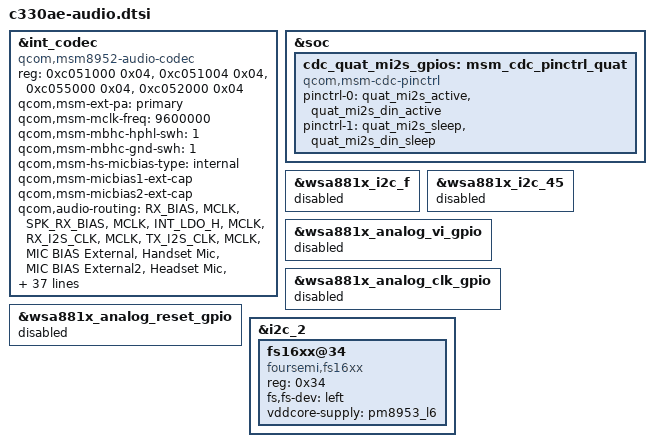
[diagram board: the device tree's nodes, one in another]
&int_codec {
	compatible = "qcom,msm8952-audio-codec";
	status = "okay";

	reg = <0xc051000 0x04>,
		  <0xc051004 0x04>,
		  <0xc055000 0x04>,
		  <0xc052000 0x04>;
	reg-names = "csr_gp_io_mux_mic_ctl",
		  "csr_gp_io_mux_spkr_ctl",
		  "csr_gp_io_lpaif_pri_pcm_pri_mode_muxsel",
		  "csr_gp_io_mux_quin_ctl";

	qcom,msm-ext-pa = "primary";
	qcom,msm-mclk-freq = <9600000>;

	qcom,msm-mbhc-hphl-swh = <1>;
	qcom,msm-mbhc-gnd-swh = <1>;
	qcom,msm-hs-micbias-type = "internal";
	qcom,msm-micbias1-ext-cap;
	qcom,msm-micbias2-ext-cap;

	qcom,audio-routing =
		"RX_BIAS", "MCLK",
		"SPK_RX_BIAS", "MCLK",
		"INT_LDO_H", "MCLK",
		"RX_I2S_CLK", "MCLK",
		"TX_I2S_CLK", "MCLK",
		"MIC BIAS External", "Handset Mic",
		"MIC BIAS External2", "Headset Mic",
		"MIC BIAS External", "Secondary Mic",
		"AMIC1", "MIC BIAS External",
		"AMIC2", "MIC BIAS External2",
		"AMIC3", "MIC BIAS External",
		"ADC1_IN", "ADC1_OUT",
		"ADC2_IN", "ADC2_OUT",
		"ADC3_IN", "ADC3_OUT",
		"PDM_IN_RX1", "PDM_OUT_RX1",
		"PDM_IN_RX2", "PDM_OUT_RX2",
		"PDM_IN_RX3", "PDM_OUT_RX3";

	/delete-property/ qcom,cdc-us-euro-gpios;
	/delete-property/ qcom,cdc-us-eu-gpios;
	/delete-property/ qcom,quin-mi2s-gpios;
	/delete-property/ asoc-wsa-codec-names;
	/delete-property/ asoc-wsa-codec-prefixes;
	/delete-property/ msm-vdd-wsa-switch-supply;
	/delete-property/ qcom,msm-vdd-wsa-switch-voltage;
	/delete-property/ qcom,msm-vdd-wsa-switch-current;

	qcom,msm-ext-I2S = "Quaternary";
	qcom,msm-ext-i2s-codec-num = <1>;
	qcom,codec-dai-left-name = "fs16xx_codec_left";
	qcom,codec-left-name = "fs16xx.2-0034";
	asoc-cpu = <&dai_pri_auxpcm>,
		<&dai_mi2s0>, <&dai_mi2s1>,
		<&dai_mi2s2>, <&dai_mi2s3>,
		<&dai_mi2s4>, <&dai_mi2s5>,
		<&sb_0_rx>, <&sb_0_tx>, <&sb_1_rx>, <&sb_1_tx>,
		<&sb_3_rx>, <&sb_3_tx>, <&sb_4_rx>, <&sb_4_tx>,
		<&bt_sco_rx>, <&bt_sco_tx>,
		<&int_fm_rx>, <&int_fm_tx>,
		<&afe_pcm_rx>, <&afe_pcm_tx>,
		<&afe_proxy_rx>, <&afe_proxy_tx>,
		<&incall_record_rx>, <&incall_record_tx>,
		<&incall_music_rx>, <&incall_music_2_rx>;
	asoc-cpu-names = "msm-dai-q6-auxpcm.1",
		"msm-dai-q6-mi2s.0", "msm-dai-q6-mi2s.1",
		"msm-dai-q6-mi2s.2", "msm-dai-q6-mi2s.3",
		"msm-dai-q6-mi2s.4", "msm-dai-q6-mi2s.6",
		"msm-dai-q6-dev.16384", "msmdai-q6-dev.16385",
		"msm-dai-q6-dev.16386", "msm-dai-q6-dev.16387",
		"msm-dai-q6-dev.16390", "msm-dai-q6-dev.16391",
		"msm-dai-q6-dev.16392", "msm-dai-q6-dev.16393",
		"msm-dai-q6-dev.12288", "msm-dai-q6-dev.12289",
		"msm-dai-q6-dev.12292", "msm-dai-q6-dev.12293",
		"msm-dai-q6-dev.224", "msm-dai-q6-dev.225",
		"msm-dai-q6-dev.241", "msm-dai-q6-dev.240",
		"msm-dai-q6-dev.32771", "msm-dai-q6-dev.32772",
		"msm-dai-q6-dev.32773", "msm-dai-q6-dev.32770";
	qcom,pri-mi2s-gpios = <&cdc_pri_mi2s_gpios>;
	qcom,quat-mi2s-gpios = <&cdc_quat_mi2s_gpios>;
	qcom,msm-I2S-quat;
};

&soc {
	cdc_quat_mi2s_gpios: msm_cdc_pinctrl_quat {
		compatible = "qcom,msm-cdc-pinctrl";
		pinctrl-names = "aud_active", "aud_sleep";
		pinctrl-0 = <&quat_mi2s_active &quat_mi2s_din_active>;
		pinctrl-1 = <&quat_mi2s_sleep &quat_mi2s_din_sleep>;
	};
};

&wsa881x_i2c_f {
	status = "disabled";
};

&wsa881x_i2c_45 {
	status = "disabled";
};

&wsa881x_analog_vi_gpio {
	status = "disabled";
};

&wsa881x_analog_clk_gpio {
	status = "disabled";
};

&wsa881x_analog_reset_gpio {
	status = "disabled";
};

&i2c_2 {
	status = "okay";

	fs16xx@34 {
		compatible = "foursemi,fs16xx";
		reg = <0x34>;
		fs,fs-dev = "left";
		vddcore-supply = <&pm8953_l6>;
		status = "okay";
	};
};
